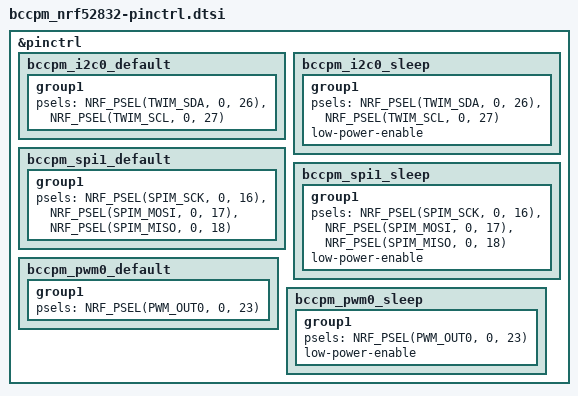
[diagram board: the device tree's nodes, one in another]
#include <zephyr/dt-bindings/pinctrl/nrf-pinctrl.h>

&pinctrl {
	bccpm_i2c0_default: bccpm_i2c0_default {
		group1 { psels = <NRF_PSEL(TWIM_SDA, 0, 26)>, <NRF_PSEL(TWIM_SCL, 0, 27)>; };
	};
	bccpm_i2c0_sleep: bccpm_i2c0_sleep {
		group1 {
			psels = <NRF_PSEL(TWIM_SDA, 0, 26)>, <NRF_PSEL(TWIM_SCL, 0, 27)>;
			low-power-enable;
		};
	};
	bccpm_spi1_default: bccpm_spi1_default {
		group1 { psels = <NRF_PSEL(SPIM_SCK, 0, 16)>, <NRF_PSEL(SPIM_MOSI, 0, 17)>, <NRF_PSEL(SPIM_MISO, 0, 18)>; };
	};
	bccpm_spi1_sleep: bccpm_spi1_sleep {
		group1 {
			psels = <NRF_PSEL(SPIM_SCK, 0, 16)>, <NRF_PSEL(SPIM_MOSI, 0, 17)>, <NRF_PSEL(SPIM_MISO, 0, 18)>;
			low-power-enable;
		};
	};
	bccpm_pwm0_default: bccpm_pwm0_default {
		group1 { psels = <NRF_PSEL(PWM_OUT0, 0, 23)>; };
	};
	bccpm_pwm0_sleep: bccpm_pwm0_sleep {
		group1 { psels = <NRF_PSEL(PWM_OUT0, 0, 23)>; low-power-enable; };
	};
};
